# STM32WB35xx register map
File version: 1.0
Registers are 32-bit, read-write, reset 0x0 unless marked. A register's access mark holds for its fields unless they carry their own. Offsets are from the block's base; [hi:lo] are bit positions.

## VREFBUF
Base 0x40010030
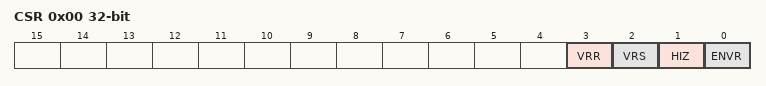
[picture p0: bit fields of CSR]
0x00 CSR — VREFBUF control and status register
  [3] VRR — Voltage reference buffer ready
  [2] VRS — Voltage reference scale
    0=SCALE0 (Voltage reference scale 0 (VREF_OUT1)); 1=SCALE1 (Voltage reference scale 1 (VREF_OUT2))
  [1] HIZ — High impedance mode
  [0] ENVR — Voltage reference buffer enable
0x04 CCR — VREFBUF calibration and control register
  [5:0] TRIM — TRIM[5:0] bits (Trimming code)

## COMP1 — Comparator
Base 0x40010200
Same registers: COMP2 0x40010204 (alternate view of COMP12_COMMON)
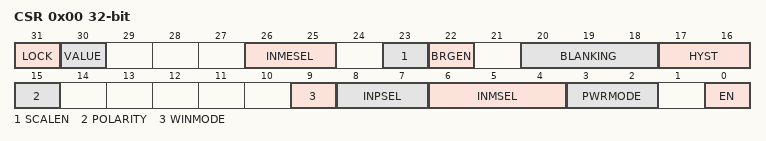
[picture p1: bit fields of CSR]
0x00 CSR — COMP control and status register
  [31] LOCK — Comparator lock
  [30] VALUE — Comparator output level
  [26:25] INMESEL — Comparator input minus extended selection
  [23] SCALEN — Comparator scaler bridge enable
  [22] BRGEN — Comparator voltage scaler enable
  [20:18] BLANKING — Comparator blanking source
    0=NONE (Comparator output without blanking); 1=TIM1_OC5 (Comparator output blanking source TIM1 OC5 (common to all COMP instances: COMP1, COMP2)); 2=TIM2_OC3 (Comparator output blanking source TIM2 OC3 (common to all COMP instances: COMP1, COMP2))
  [17:16] HYST — Comparator hysteresis
    0=NONE (No hysteresis); 1=LOW (Hysteresis level low); 2=MEDIUM (Hysteresis level medium); 3=HIGH (Hysteresis level high)
  [15] POLARITY — Comparator output polarity
    0=NONINVERTED (COMP output polarity is not inverted: comparator output is high when the plus (non-inverting) input is at a higher voltage than the minus (inverting) input); 1=INVERTED (COMP output polarity is inverted: comparator output is low when the plus (non-inverting) input is at a lower voltage than the minus (inverting) input)
  [9] WINMODE — Pair of comparators window mode. Bit intended to be used with COMP common instance (COMP_Common_TypeDef)
    0=DISABLE (Window mode disable: Comparators 1 and 2 are independent); 1=COMP1_INPUT_PLUS_COMMON (Window mode enable: Comparators instances pair COMP1 and COMP2 have their input plus connected together. The common input is COMP1 input plus (COMP2 input plus is no more accessible).)
  [8:7] INPSEL — Comparator input plus selection
    0=IO1 (Comparator input plus connected to IO1 (pin PC5 for COMP1 (except device STM32WB35xx), pin PB4 for COMP2). Note: On STM32WB series, parameter not available on devices: STM32WB10xx, STM32WB15xx, STM32WB1Mxx.); 1=IO2 (Comparator input plus connected to IO2 (pin PB2 for COMP1, pin PB6 for COMP2)); 2=IO3 (Comparator input plus connected to IO3 (pin PA1 for COMP1, pin PA3 for COMP2))
  [6:4] INMSEL — Comparator input minus selection
  [3:2] PWRMODE — Comparator power mode
    0=HIGHSPEED (COMP power mode to high speed); 1=MEDIUMSPEED (COMP power mode to medium speed); 3=ULTRALOWPOWER (COMP power mode to ultra-low power)
  [0] EN — Comparator enable

## COMP12_COMMON
Base 0x40010204
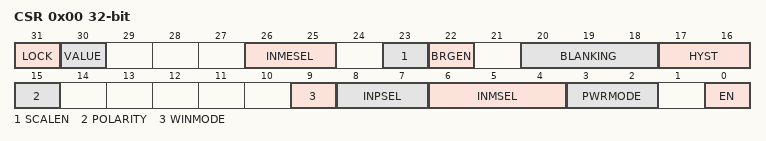
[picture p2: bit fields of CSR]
0x00 CSR — COMP control and status register, used for bits common to several COMP instances
  [31] LOCK — Comparator lock
  [30] VALUE — Comparator output level
  [26:25] INMESEL — Comparator input minus extended selection
  [23] SCALEN — Comparator scaler bridge enable
  [22] BRGEN — Comparator voltage scaler enable
  [20:18] BLANKING — Comparator blanking source
    0=NONE (Comparator output without blanking); 1=TIM1_OC5 (Comparator output blanking source TIM1 OC5 (common to all COMP instances: COMP1, COMP2)); 2=TIM2_OC3 (Comparator output blanking source TIM2 OC3 (common to all COMP instances: COMP1, COMP2))
  [17:16] HYST — Comparator hysteresis
    0=NONE (No hysteresis); 1=LOW (Hysteresis level low); 2=MEDIUM (Hysteresis level medium); 3=HIGH (Hysteresis level high)
  [15] POLARITY — Comparator output polarity
    0=NONINVERTED (COMP output polarity is not inverted: comparator output is high when the plus (non-inverting) input is at a higher voltage than the minus (inverting) input); 1=INVERTED (COMP output polarity is inverted: comparator output is low when the plus (non-inverting) input is at a lower voltage than the minus (inverting) input)
  [9] WINMODE — Pair of comparators window mode. Bit intended to be used with COMP common instance (COMP_Common_TypeDef)
    0=DISABLE (Window mode disable: Comparators 1 and 2 are independent); 1=COMP1_INPUT_PLUS_COMMON (Window mode enable: Comparators instances pair COMP1 and COMP2 have their input plus connected together. The common input is COMP1 input plus (COMP2 input plus is no more accessible).)
  [8:7] INPSEL — Comparator input plus selection
    0=IO1 (Comparator input plus connected to IO1 (pin PC5 for COMP1 (except device STM32WB35xx), pin PB4 for COMP2). Note: On STM32WB series, parameter not available on devices: STM32WB10xx, STM32WB15xx, STM32WB1Mxx.); 1=IO2 (Comparator input plus connected to IO2 (pin PB2 for COMP1, pin PB6 for COMP2)); 2=IO3 (Comparator input plus connected to IO3 (pin PA1 for COMP1, pin PA3 for COMP2))
  [6:4] INMSEL — Comparator input minus selection
  [3:2] PWRMODE — Comparator power mode
    0=HIGHSPEED (COMP power mode to high speed); 1=MEDIUMSPEED (COMP power mode to medium speed); 3=ULTRALOWPOWER (COMP power mode to ultra-low power)
  [0] EN — Comparator enable
